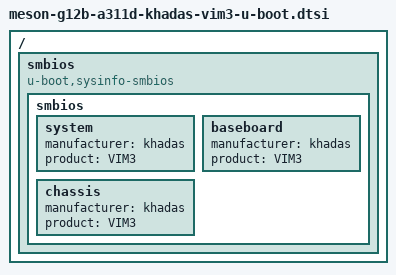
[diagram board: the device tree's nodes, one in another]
// SPDX-License-Identifier: (GPL-2.0+ OR MIT)
/*
 * Copyright (c) 2020 BayLibre, SAS
 * Author: Neil Armstrong <narmstrong@baylibre.com>
 */

#include "meson-g12-common-u-boot.dtsi"
#include "meson-khadas-vim3-u-boot.dtsi"

/ {
	smbios {
		compatible = "u-boot,sysinfo-smbios";

		smbios {
			system {
				manufacturer = "khadas";
				product = "VIM3";
			};

			baseboard {
				manufacturer = "khadas";
				product = "VIM3";
			};

			chassis {
				manufacturer = "khadas";
				product = "VIM3";
			};
		};
	};
};
